AUTOSAR XML (schema 4-2-1)
package /DataType
  base type my_uint8: category=FIXED_LENGTH, base-type-size=8, base-type-encoding=NONE, native-declaration=unsigned char
  impl type my_uint8: category=VALUE, base-type=my_uint8, range phys 0..255, raw 0..255
  impl type CAN_FRAME: category=ARRAY
    element Array_Element: category=VALUE, array-size=8, array-size-handling=ALL-INDICES-SAME-ARRAY-SIZE, array-size-semantics=FIXED-SIZE, base-type=my_uint8, range phys 0..255, raw 0..255
package /Interfacing
  sender receiver interface SRI_CAN_Frame
    data CAN_Frame: type=CAN_FRAME, init-value=[0]
  sender receiver interface SRI_LED_Warning
    data LED_Warning: type=my_uint8, init-value=0
  client server interface CSI_Call_Subsystem
    operation Call_Subsystem: possible-error=[E_NOT_OK, E_OK]
      arg CAN_Frame: type=CAN_FRAME, direction=IN
    error E_NOT_OK: error-code=0
    error E_OK: error-code=1
  sender receiver interface SRI_LCD_Warning
    data LCD_Warning: type=my_uint8, init-value=0
  sender receiver interface SRI_Motor_Speed
    data Motor_Speed: type=my_uint8, init-value=0
package /SWCs
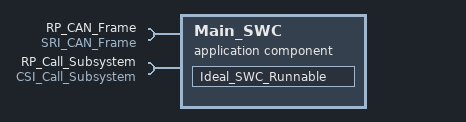
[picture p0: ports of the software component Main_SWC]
  application sw component type Main_SWC
    require port RP_CAN_Frame: required-interface=SRI_CAN_Frame
    require port RP_Call_Subsystem: required-interface=CSI_Call_Subsystem
    behavior IB_Ideal_SWC
      data received event Frame_Received_Event: start-on-event=Ideal_SWC_Runnable, data=CAN_Frame
      runnable Ideal_SWC_Runnable: symbol=Ideal_SWC
        data-read-access:
          access DR_Access: accessed-variable=RP_CAN_Frame.CAN_Frame
        sync call SYN_Server_Call: operation=RP_Call_Subsystem.Call_Subsystem
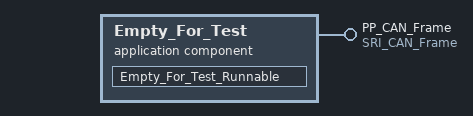
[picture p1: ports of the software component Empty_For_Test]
  application sw component type Empty_For_Test
    provide port PP_CAN_Frame: provided-interface=SRI_CAN_Frame
    behavior IB_Empty_For_Test
      runnable Empty_For_Test_Runnable: symbol=Empty_For_Test
        data-write-access:
          access DW_Access: accessed-variable=PP_CAN_Frame.CAN_Frame
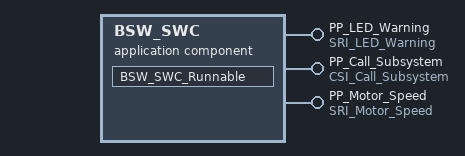
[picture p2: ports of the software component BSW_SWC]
  application sw component type BSW_SWC
    provide port PP_LED_Warning: provided-interface=SRI_LED_Warning
    provide port PP_Call_Subsystem: provided-interface=CSI_Call_Subsystem
    provide port PP_Motor_Speed: provided-interface=SRI_Motor_Speed
    behavior IB_BSW_SWC
      operation invoked event OIE_BSW_Runnable: start-on-event=BSW_SWC_Runnable, operation=PP_Call_Subsystem.Call_Subsystem
      runnable BSW_SWC_Runnable: symbol=BSW_SWC
        data-write-access:
          access DW_LED_Warning: accessed-variable=PP_LED_Warning.LED_Warning
          access DW_Motor_Speed: accessed-variable=PP_Motor_Speed.Motor_Speed
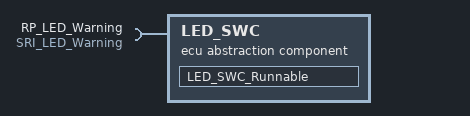
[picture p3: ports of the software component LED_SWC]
  ecu abstraction sw component type LED_SWC
    require port RP_LED_Warning: required-interface=SRI_LED_Warning
    behavior IB_LED_SWC
      data received event LED_Warning_Received_Event: start-on-event=LED_SWC_Runnable, data=LED_Warning
      runnable LED_SWC_Runnable: symbol=LED_SWC
        data-read-access:
          access DR_LED_Warning: accessed-variable=RP_LED_Warning.LED_Warning
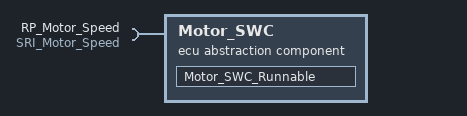
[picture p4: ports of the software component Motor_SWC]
  ecu abstraction sw component type Motor_SWC
    require port RP_Motor_Speed: required-interface=SRI_Motor_Speed
    behavior IB_Motor_Speed
      data received event Motor_Speed_Received_Event: start-on-event=Motor_SWC_Runnable, data=Motor_Speed
      runnable Motor_SWC_Runnable: symbol=Motor_SWC
        data-read-access:
          access DR_Motor_Speed: accessed-variable=RP_Motor_Speed.Motor_Speed
package /Composition
  composition sw component type Composition_SWC
    5 x component:
      Main_SWC: type=Main_SWC
      Empty_For_Test: type=Empty_For_Test
      LED_SWC: type=LED_SWC
      BSW_SWC: type=BSW_SWC
      Motor_SWC: type=Motor_SWC
    connect Empty_For_Test.PP_CAN_Frame -> Main_SWC.RP_CAN_Frame
    connect BSW_SWC.PP_LED_Warning -> LED_SWC.RP_LED_Warning
    connect BSW_SWC.PP_Call_Subsystem -> Main_SWC.RP_Call_Subsystem
    connect BSW_SWC.PP_Motor_Speed -> Motor_SWC.RP_Motor_Speed
